AUTOSAR XML (schema 4-2-2)
package /ComponentTypes
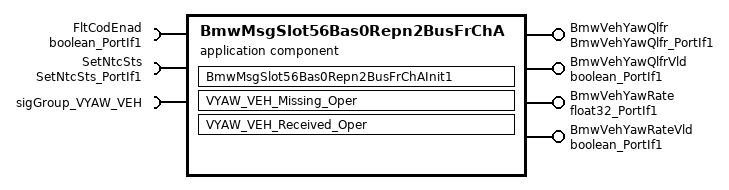
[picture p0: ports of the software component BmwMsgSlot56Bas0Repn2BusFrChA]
  application sw component type BmwMsgSlot56Bas0Repn2BusFrChA
    4 x provide port:
      BmwVehYawQlfr: nonqueued-sender-com-spec{data-element=Val, init-value=15}, provided-interface=BmwVehYawQlfr_PortIf1
      BmwVehYawQlfrVld: nonqueued-sender-com-spec{data-element=Logl, init-value=0}, provided-interface=boolean_PortIf1
      BmwVehYawRate: nonqueued-sender-com-spec{data-element=Val, init-value=0}, provided-interface=float32_PortIf1
      BmwVehYawRateVld: nonqueued-sender-com-spec{data-element=Logl, init-value=0}, provided-interface=boolean_PortIf1
    require port FltCodEnad: nonqueued-receiver-com-spec{data-element=Logl, filter=data-filter-type=ALWAYS, init-value=1}, required-interface=boolean_PortIf1
    require port SetNtcSts: client-com-spec=Oper, required-interface=SetNtcSts_PortIf1
    require port sigGroup_VYAW_VEH: nonqueued-receiver-com-spec{data-element=sigGroup_VYAW_VEH, uses-end-to-end-protection=true, alive-timeout=0.015, enable-update=true, filter=data-filter-type=ALWAYS, init-value=fields=[QU_VYAW_VEH:0, VYAW_VEH_ERR_AMP:0, VYAW_VEH:32768, VYAW_VEH_dummy_12_15:0, CRC_VYAW_VEH:0, ALIV_VYAW_VEH:0]}, required-interface=sigGroup_VYAW_VEH
    behavior BmwMsgSlot56Bas0Repn2BusFrChA_InternalBehavior
      ar-typed-per-instance-memorys:
        12 x data, all with sw-calibration-access=READ-ONLY:
          AlvFaildCnt: type=uint8
          AlvPassdCnt: type=uint8
          BmwVehYawQlfrPrev: type=BmwVehYawQlfr1
          BmwVehYawRatePrev: type=float32
          CrcFaildCnt: type=uint8
          CrcPassdCnt: type=uint8
          MissingMsgCnt: type=uint8
          QuVyawVehFaildCnt: type=uint8
          QuVyawVehPassdCnt: type=uint8
          RxdMsgCnt: type=uint8
          VyawVehFaildCnt: type=uint8
          VyawVehPassdCnt: type=uint8
      init event BmwMsgSlot56Bas0Repn2BusFrChA_InitEvent: start-on-event=BmwMsgSlot56Bas0Repn2BusFrChAInit1
      data receive error event DRET_VYAW_VEH_Missing_Oper_sigGroup_VYAW_VEH_sigGroup_VYAW_VEH: start-on-event=VYAW_VEH_Missing_Oper, data=sigGroup_VYAW_VEH.sigGroup_VYAW_VEH
      data received event DRT_VYAW_VEH_Received_Oper_sigGroup_VYAW_VEH_sigGroup_VYAW_VEH: start-on-event=VYAW_VEH_Received_Oper, data=sigGroup_VYAW_VEH.sigGroup_VYAW_VEH
      port-api-options:
        enable-take-address=false, error-handling=NO-TRANSFORMER-ERROR-HANDLING, indirect-api=false, port=BmwVehYawQlfr
        enable-take-address=false, error-handling=NO-TRANSFORMER-ERROR-HANDLING, indirect-api=false, port=BmwVehYawQlfrVld
        enable-take-address=false, error-handling=NO-TRANSFORMER-ERROR-HANDLING, indirect-api=false, port=BmwVehYawRate
        enable-take-address=false, error-handling=NO-TRANSFORMER-ERROR-HANDLING, indirect-api=false, port=BmwVehYawRateVld
        enable-take-address=false, error-handling=NO-TRANSFORMER-ERROR-HANDLING, indirect-api=false, port=FltCodEnad
        enable-take-address=false, error-handling=NO-TRANSFORMER-ERROR-HANDLING, indirect-api=false, port=SetNtcSts
        enable-take-address=false, error-handling=NO-TRANSFORMER-ERROR-HANDLING, indirect-api=false, port=sigGroup_VYAW_VEH
      runnable BmwMsgSlot56Bas0Repn2BusFrChAInit1
        data-receive-point-by-arguments:
          access REC_FltCodEnad_Logl: accessed-variable=FltCodEnad.Logl
          access REC_sigGroup_VYAW_VEH_sigGroup_VYAW_VEH: accessed-variable=sigGroup_VYAW_VEH.sigGroup_VYAW_VEH
        data-send-points:
          4 x access:
            SEND_BmwVehYawQlfr_Val: accessed-variable=BmwVehYawQlfr.Val
            SEND_BmwVehYawQlfrVld_Logl: accessed-variable=BmwVehYawQlfrVld.Logl
            SEND_BmwVehYawRate_Val: accessed-variable=BmwVehYawRate.Val
            SEND_BmwVehYawRateVld_Logl: accessed-variable=BmwVehYawRateVld.Logl
        sync call SC_SetNtcSts_Oper: operation=SetNtcSts.Oper, timeout=0
      runnable VYAW_VEH_Missing_Oper
        data-receive-point-by-arguments:
          access REC_FltCodEnad_Logl: accessed-variable=FltCodEnad.Logl
          access REC_sigGroup_VYAW_VEH_sigGroup_VYAW_VEH: accessed-variable=sigGroup_VYAW_VEH.sigGroup_VYAW_VEH
        data-send-points:
          4 x access:
            SEND_BmwVehYawQlfr_Val: accessed-variable=BmwVehYawQlfr.Val
            SEND_BmwVehYawQlfrVld_Logl: accessed-variable=BmwVehYawQlfrVld.Logl
            SEND_BmwVehYawRate_Val: accessed-variable=BmwVehYawRate.Val
            SEND_BmwVehYawRateVld_Logl: accessed-variable=BmwVehYawRateVld.Logl
        sync call SC_SetNtcSts_Oper: operation=SetNtcSts.Oper, timeout=0
      runnable VYAW_VEH_Received_Oper
        data-receive-point-by-arguments:
          access REC_FltCodEnad_Logl: accessed-variable=FltCodEnad.Logl
          access REC_sigGroup_VYAW_VEH_sigGroup_VYAW_VEH: accessed-variable=sigGroup_VYAW_VEH.sigGroup_VYAW_VEH
        data-send-points:
          4 x access:
            SEND_BmwVehYawQlfr_Val: accessed-variable=BmwVehYawQlfr.Val
            SEND_BmwVehYawQlfrVld_Logl: accessed-variable=BmwVehYawQlfrVld.Logl
            SEND_BmwVehYawRate_Val: accessed-variable=BmwVehYawRate.Val
            SEND_BmwVehYawRateVld_Logl: accessed-variable=BmwVehYawRateVld.Logl
        sync call SC_SetNtcSts_Oper: operation=SetNtcSts.Oper, timeout=0
  swc implementation BmwMsgSlot56Bas0Repn2BusFrChA_Implementation: behavior=BmwMsgSlot56Bas0Repn2BusFrChA_InternalBehavior
    code-descriptors:
      code Default: artifact-descriptors=autosar-engineering-object={short-label=Default, category=SWSRC}
